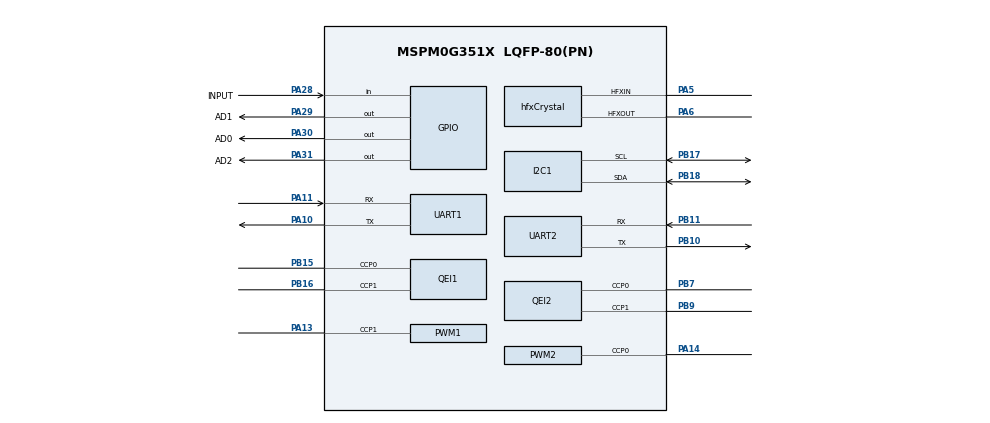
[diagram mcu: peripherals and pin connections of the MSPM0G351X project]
/**
 *
 * @cliArgs --device "MSPM0G351X" --part "Default" --package "LQFP-80(PN)" --product "mspm0_sdk@2.11.00.07"
 * @versions {"tool":"1.28.0+4712"}
 */

/**
 * Import the modules used in this configuration.
 */
const GPIO          = scripting.addModule("/ti/driverlib/GPIO", {}, false);
const GPIO1         = GPIO.addInstance();
const GPIO2         = GPIO.addInstance();
const GPIO3         = GPIO.addInstance();
const GPIO4         = GPIO.addInstance();
const I2C           = scripting.addModule("/ti/driverlib/I2C", {}, false);
const I2C1          = I2C.addInstance();
const UART          = scripting.addModule("/ti/driverlib/UART", {}, false);
const UART1         = UART.addInstance();
const UART2         = UART.addInstance();
const PWM           = scripting.addModule("/ti/driverlib/PWM", {}, false);
const PWM1          = PWM.addInstance();
const PWM2          = PWM.addInstance();
const TIMER          = scripting.addModule("/ti/driverlib/TIMER", {}, false);
const TIMER1         = TIMER.addInstance();
const QEI            = scripting.addModule("/ti/driverlib/QEI", {}, false);
const QEI1           = QEI.addInstance();
const QEI2           = QEI.addInstance();
const SYSCTL        = scripting.addModule("/ti/driverlib/SYSCTL");
const ProjectConfig = scripting.addModule("/ti/project_config/ProjectConfig");

/**
 * Write custom configuration values to the imported modules.
 */
const divider5       = system.clockTree["PLL_CLK1_DIV"];
divider5.divideValue = 4;

const divider6       = system.clockTree["PLL_CLK2X_DIV"];
divider6.divideValue = 4;

const divider7       = system.clockTree["PLL_PDIV"];
divider7.divideValue = 2;

const divider9       = system.clockTree["UDIV"];
divider9.divideValue = 2;

const multiplier2         = system.clockTree["PLL_QDIV"];
multiplier2.multiplyValue = 8;

const muxHfSource       = system.clockTree["EXHFMUX"];
muxHfSource.inputSelect = "EXHFMUX_XTAL";

const muxPllSource       = system.clockTree["SYSPLLMUX"];
muxPllSource.inputSelect = "zSYSPLLMUX_HFCLK";

const hfxCrystal                        = system.clockTree["HFXT"];
hfxCrystal.enable                       = true;
hfxCrystal.inputFreq                    = 40;
hfxCrystal.HFCLKMonitor                 = true;
hfxCrystal.HFXTStartup                  = 100;
hfxCrystal.peripheral.$assign           = "SYSCTL";
hfxCrystal.peripheral.hfxInPin.$assign  = "PA5";
hfxCrystal.peripheral.hfxOutPin.$assign = "PA6";

const mux8       = system.clockTree["HSCLKMUX"];
mux8.inputSelect = "HSCLKMUX_SYSPLL2X";

GPIO1.$name                          = "GPIO_LED";
GPIO1.associatedPins.create(3);
GPIO1.associatedPins[0].assignedPort = "PORTB";
GPIO1.associatedPins[0].assignedPin  = "1";
GPIO1.associatedPins[0].initialValue = "SET";
GPIO1.associatedPins[0].$name        = "RED";
GPIO1.associatedPins[1].initialValue = "SET";
GPIO1.associatedPins[1].assignedPort = "PORTB";
GPIO1.associatedPins[1].assignedPin  = "0";
GPIO1.associatedPins[1].$name        = "GREEN";
GPIO1.associatedPins[2].initialValue = "SET";
GPIO1.associatedPins[2].assignedPort = "PORTA";
GPIO1.associatedPins[2].assignedPin  = "7";
GPIO1.associatedPins[2].$name        = "BLUE";

const Board = scripting.addModule("/ti/driverlib/Board", {}, false);

GPIO2.$name                              = "GPIO_Key";
GPIO2.associatedPins.create(3);
GPIO2.associatedPins[0].$name            = "Key0";
GPIO2.associatedPins[0].direction        = "INPUT";
GPIO2.associatedPins[0].assignedPort     = "PORTA";
GPIO2.associatedPins[0].assignedPin      = "16";
GPIO2.associatedPins[0].internalResistor = "PULL_UP";
GPIO2.associatedPins[0].ioStructure      = "SD";
GPIO2.associatedPins[1].$name            = "Key1";
GPIO2.associatedPins[1].direction        = "INPUT";
GPIO2.associatedPins[1].internalResistor = "PULL_UP";
GPIO2.associatedPins[1].assignedPort     = "PORTC";
GPIO2.associatedPins[1].assignedPin      = "0";
GPIO2.associatedPins[1].ioStructure      = "SD";
GPIO2.associatedPins[2].$name            = "Key2";
GPIO2.associatedPins[2].direction        = "INPUT";
GPIO2.associatedPins[2].internalResistor = "PULL_UP";
GPIO2.associatedPins[2].assignedPort     = "PORTC";
GPIO2.associatedPins[2].assignedPin      = "1";

GPIO3.$name                          = "GPIO_MOTOR";
GPIO3.associatedPins.create(2);
GPIO3.associatedPins[0].$name        = "RIGHT_DIR";
GPIO3.associatedPins[0].ioStructure  = "SD";
GPIO3.associatedPins[0].assignedPort = "PORTA";
GPIO3.associatedPins[0].assignedPin  = "15";
GPIO3.associatedPins[1].$name        = "LEFT_DIR";
GPIO3.associatedPins[1].assignedPort = "PORTA";
GPIO3.associatedPins[1].assignedPin  = "12";

GPIO4.$name                          = "GPIO_LOOP";
GPIO4.associatedPins.create(4);
GPIO4.associatedPins[0].$name        = "AD0";
GPIO4.associatedPins[0].direction    = "OUTPUT";
GPIO4.associatedPins[0].initialValue = "CLEARED";
GPIO4.associatedPins[0].assignedPort = "PORTA";
GPIO4.associatedPins[0].assignedPin  = "30";
GPIO4.associatedPins[0].pin.$assign  = "PA30";
GPIO4.associatedPins[1].$name        = "AD1";
GPIO4.associatedPins[1].direction    = "OUTPUT";
GPIO4.associatedPins[1].initialValue = "CLEARED";
GPIO4.associatedPins[1].assignedPort = "PORTA";
GPIO4.associatedPins[1].assignedPin  = "29";
GPIO4.associatedPins[1].pin.$assign  = "PA29";
GPIO4.associatedPins[2].$name        = "AD2";
GPIO4.associatedPins[2].direction    = "OUTPUT";
GPIO4.associatedPins[2].initialValue = "CLEARED";
GPIO4.associatedPins[2].assignedPort = "PORTA";
GPIO4.associatedPins[2].assignedPin  = "31";
GPIO4.associatedPins[2].pin.$assign  = "PA31";
GPIO4.associatedPins[3].$name        = "INPUT";
GPIO4.associatedPins[3].direction    = "INPUT";
GPIO4.associatedPins[3].assignedPort = "PORTA";
GPIO4.associatedPins[3].assignedPin  = "28";
GPIO4.associatedPins[3].pin.$assign  = "PA28";

I2C1.$name                             = "I2C_OLED";
I2C1.basicEnableController             = true;
I2C1.basicControllerBusSpeed           = 400000;
I2C1.peripheral.$assign                = "I2C0";
I2C1.peripheral.sclPin.$assign         = "PB17";
I2C1.peripheral.sdaPin.$assign         = "PB18";
I2C1.sdaPinConfig.$name                = "ti_driverlib_gpio_GPIOPinOledSda";
I2C1.sdaPinConfig.hideOutputInversion  = scripting.forceWrite(false);
I2C1.sdaPinConfig.onlyInternalResistor = scripting.forceWrite(false);
I2C1.sdaPinConfig.passedPeripheralType = scripting.forceWrite("Digital");
I2C1.sclPinConfig.$name                = "ti_driverlib_gpio_GPIOPinOledScl";
I2C1.sclPinConfig.hideOutputInversion  = scripting.forceWrite(false);
I2C1.sclPinConfig.onlyInternalResistor = scripting.forceWrite(false);
I2C1.sclPinConfig.passedPeripheralType = scripting.forceWrite("Digital");

UART1.$name                             = "UART_BLUETOOTH";
UART1.targetBaudRate                    = 115200;
UART1.enableFIFO                        = true;
UART1.rxFifoThreshold                   = "DL_UART_RX_FIFO_LEVEL_ONE_ENTRY";
UART1.txFifoThreshold                   = "DL_UART_TX_FIFO_LEVEL_ONE_ENTRY";
UART1.enabledInterrupts                 = ["DMA_DONE_RX", "DMA_DONE_TX", "EOT_DONE"];
UART1.enabledDMARXTriggers              = "DL_UART_DMA_INTERRUPT_RX";
UART1.enabledDMATXTriggers              = "DL_UART_DMA_INTERRUPT_TX";
UART1.peripheral.$assign                = "UART0";
UART1.peripheral.rxPin.$assign          = "PA11";
UART1.peripheral.txPin.$assign          = "PA10";
UART1.DMA_CHANNEL_RX.$name              = "DMA_CH1";
UART1.DMA_CHANNEL_RX.addressMode        = "f2b";
UART1.DMA_CHANNEL_RX.srcLength          = "BYTE";
UART1.DMA_CHANNEL_RX.dstLength          = "BYTE";
UART1.DMA_CHANNEL_RX.peripheral.$assign = "DMA_CH1";
UART1.DMA_CHANNEL_TX.$name              = "DMA_CH0";
UART1.DMA_CHANNEL_TX.addressMode        = "b2f";
UART1.DMA_CHANNEL_TX.srcLength          = "BYTE";
UART1.DMA_CHANNEL_TX.dstLength          = "BYTE";
UART1.DMA_CHANNEL_TX.peripheral.$assign = "DMA_CH0";

UART2.$name                    = "UART_IMU";
UART2.targetBaudRate           = 115200;
UART2.enableFIFO               = true;
UART2.rxFifoThreshold          = "DL_UART_RX_FIFO_LEVEL_ONE_ENTRY";
UART2.txFifoThreshold          = "DL_UART_TX_FIFO_LEVEL_EMPTY";
UART2.enabledInterrupts        = ["RX"];
UART2.peripheral.$assign       = "UART4";
UART2.peripheral.rxPin.$assign = "PB11";
UART2.peripheral.txPin.$assign = "PB10";

PWM1.$name                              = "PWM_LEFT";
PWM1.ccIndex                            = [1];
PWM1.clockDivider                       = 2;
PWM1.ccp1PinConfig.$name                = "ti_driverlib_gpio_GPIOPinGeneric1";
PWM1.ccp1PinConfig.direction            = scripting.forceWrite("OUTPUT");
PWM1.ccp1PinConfig.hideOutputInversion  = scripting.forceWrite(false);
PWM1.ccp1PinConfig.onlyInternalResistor = scripting.forceWrite(false);
PWM1.ccp1PinConfig.passedPeripheralType = scripting.forceWrite("Digital");
PWM1.peripheral.$assign                 = "TIMG0";
PWM1.peripheral.ccp1Pin.$assign         = "PA13";
PWM1.PWM_CHANNEL_1.$name                = "ti_driverlib_pwm_PWMTimerCC0";

PWM2.$name                              = "PWM_RIGHT";
PWM2.ccIndex                            = [0];
PWM2.clockDivider                       = 4;
PWM2.PWM_CHANNEL_0.$name                = "ti_driverlib_pwm_PWMTimerCC1";
PWM2.ccp0PinConfig.direction            = scripting.forceWrite("OUTPUT");
PWM2.ccp0PinConfig.hideOutputInversion  = scripting.forceWrite(false);
PWM2.ccp0PinConfig.onlyInternalResistor = scripting.forceWrite(false);
PWM2.ccp0PinConfig.passedPeripheralType = scripting.forceWrite("Digital");
PWM2.ccp0PinConfig.$name                = "ti_driverlib_gpio_GPIOPinGeneric0";
PWM2.peripheral.$assign                 = "TIMG12";
PWM2.peripheral.ccp0Pin.$assign         = "PA14";

TIMER1.$name              = "TIMER_PID";
TIMER1.timerPeriod        = "10 ms";
TIMER1.timerMode          = "PERIODIC";
TIMER1.timerClkPrescale   = 16;
TIMER1.interrupts         = ["ZERO"];
TIMER1.peripheral.$assign = "TIMG6";

QEI1.$name                      = "QEI_LEFT";
QEI1.peripheral.$assign         = "TIMG8";
QEI1.peripheral.ccp0Pin.$assign = "PB15";
QEI1.peripheral.ccp1Pin.$assign = "PB16";

QEI2.$name                      = "QEI_RIGHT";
QEI2.peripheral.$assign         = "TIMG9";
QEI2.peripheral.ccp0Pin.$assign = "PB7";
QEI2.peripheral.ccp1Pin.$assign = "PB9";

SYSCTL.MCLKSource            = "HSCLK";
SYSCTL.HSCLKSource           = "SYSPLLCLK2X";
SYSCTL.useHFCLK_Manual       = true;
SYSCTL.HFCLKSource           = "HFXT";
SYSCTL.HFCLK_Freq            = 40000000;
SYSCTL.SYSPLLSource          = "HFCLK";
SYSCTL.SYSPLL_CLK1En         = true;
SYSCTL.SYSPLL_CLK2XEn        = true;
SYSCTL.SYSPLL_CLK2XDiv       = 1;
SYSCTL.SYSPLL_Qdiv           = 5;
SYSCTL.validateClkStatus     = true;
SYSCTL.forceDefaultClkConfig = true;
SYSCTL.clockTreeEn           = true;

ProjectConfig.deviceSpin = "MSPM0G3519";

/**
 * Pinmux solution for unlocked pins/peripherals. This ensures that minor changes to the automatic solver in a future
 * version of the tool will not impact the pinmux you originally saw.  These lines can be completely deleted in order to
 * re-solve from scratch.
 */
GPIO1.associatedPins[0].pin.$suggestSolution = "PB1";
GPIO1.associatedPins[1].pin.$suggestSolution = "PB0";
GPIO1.associatedPins[2].pin.$suggestSolution = "PA7";
Board.peripheral.$suggestSolution            = "DEBUGSS";
Board.peripheral.swclkPin.$suggestSolution   = "PA20";
Board.peripheral.swdioPin.$suggestSolution   = "PA19";
GPIO2.associatedPins[0].pin.$suggestSolution = "PA16";
GPIO2.associatedPins[1].pin.$suggestSolution = "PC0";
GPIO2.associatedPins[2].pin.$suggestSolution = "PC1";
GPIO3.associatedPins[0].pin.$suggestSolution = "PA15";
GPIO3.associatedPins[1].pin.$suggestSolution = "PA12";
